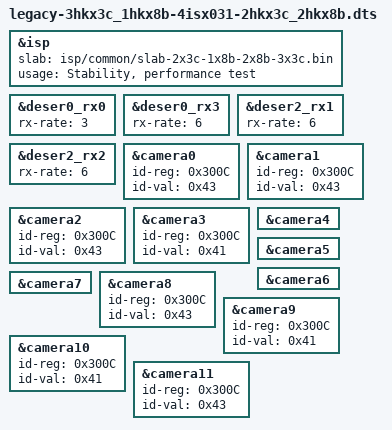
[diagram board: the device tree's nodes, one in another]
/dts-v1/;
/plugin/;

#include "../common/isp-csi-map.dtsi"
#include "base-isp.dtsi"
#include "base-csi-deser-camera.dtsi"
#include "base-desers-3max96724.dtsi"

&isp {
	slab = "isp/common/slab-2x3c-1x8b-2x8b-3x3c.bin";
	usage = "Stability, performance test";
};
&deser0_rx0 {
	rx-rate = <3>;
};
&deser0_rx3 {
	rx-rate = <6>;
};
&deser2_rx1 {
	rx-rate = <6>;
};
&deser2_rx2 {
	rx-rate = <6>;
};
&camera0 {
	#include "../cameras/ox03c_raw14_hk_1920x1080.dtsi"
	id-reg = <0x300C>;
	id-val = <0x43>;
	status = "okay";
};
&camera1 {
	#include "../cameras/ox03c_raw14_hk_1920x1080.dtsi"
	id-reg = <0x300C>;
	id-val = <0x43>;
	status = "okay";
};
&camera2 {
	#include "../cameras/ox03c_raw14_hk_1920x1080.dtsi"
	id-reg = <0x300C>;
	id-val = <0x43>;
	status = "okay";
};
&camera3 {
	#include "../cameras/ox08b_raw14_hk_1920x1080.dtsi"
	id-reg = <0x300C>;
	id-val = <0x41>;
	status = "okay";
};
&camera4 {
	#include "../cameras/isx031_yuv_cd1_1920x1536.dtsi"
	status = "okay";
};
&camera5 {
	#include "../cameras/isx031_yuv_cd1_1920x1536.dtsi"
	status = "okay";
};
&camera6 {
	#include "../cameras/isx031_yuv_cd1_1920x1536.dtsi"
	status = "okay";
};
&camera7 {
	#include "../cameras/isx031_yuv_cd1_1920x1536.dtsi"
	status = "okay";
};
&camera8 {
	#include "../cameras/ox03c_raw14_hk_1920x1080.dtsi"
	id-reg = <0x300C>;
	id-val = <0x43>;
	status = "okay";
};
&camera9 {
	#include "../cameras/ox08b_raw14_hk_1920x1080.dtsi"
	id-reg = <0x300C>;
	id-val = <0x41>;
	status = "okay";
};
&camera10 {
	#include "../cameras/ox08b_raw14_hk_1920x1080.dtsi"
	id-reg = <0x300C>;
	id-val = <0x41>;
	status = "okay";
};
&camera11 {
	#include "../cameras/ox03c_raw14_hk_1920x1080.dtsi"
	id-reg = <0x300C>;
	id-val = <0x43>;
	status = "okay";
};
